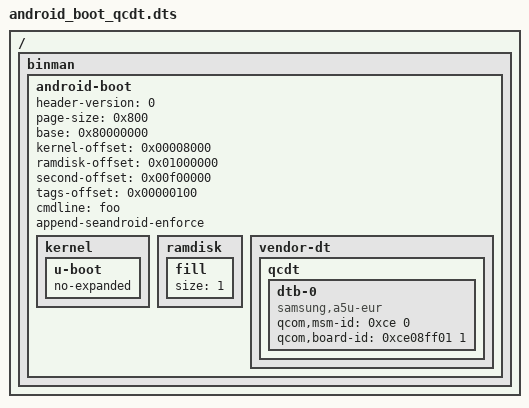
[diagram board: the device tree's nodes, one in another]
// SPDX-License-Identifier: GPL-2.0+

/dts-v1/;

/ {
	#address-cells = <1>;
	#size-cells = <1>;

	binman {
		android-boot {
			header-version = <0>;
			page-size = <0x800>;
			base = <0x80000000>;
			kernel-offset = <0x00008000>;
			ramdisk-offset = <0x01000000>;
			second-offset = <0x00f00000>;
			tags-offset = <0x00000100>;
			cmdline = "foo";
			append-seandroid-enforce;

			kernel {
				u-boot {
					no-expanded;
				};
			};

			ramdisk {
				fill {
					size = <1>;
				};
			};

			vendor-dt {
				qcdt {
					dtb-0 {
						compatible = "samsung,a5u-eur", "qcom,msm8916";
						qcom,msm-id = <0xce 0>;
						qcom,board-id = <0xce08ff01 1>;
					};
				};
			};
		};
	};
};
